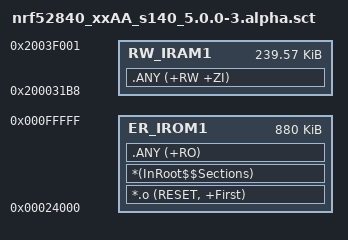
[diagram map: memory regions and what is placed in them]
; ****************************************
; *** Scatter-Loading Description File ***
; ****************************************

; Scatter file for a program IN APPLICATION SPACE, accessing the softdevice
; through SVCs.

LR_IROM1 0x00024000 0x000DC000 {  ; Load region size_region
  ER_IROM1 0x00024000 0x000DC000 {
   *.o (RESET, +First)
   *(InRoot$$Sections)
   .ANY (+RO)
  }

  RW_IRAM1 0x200031B8 0x0003BE4A {
   .ANY (+RW +ZI)
  }
